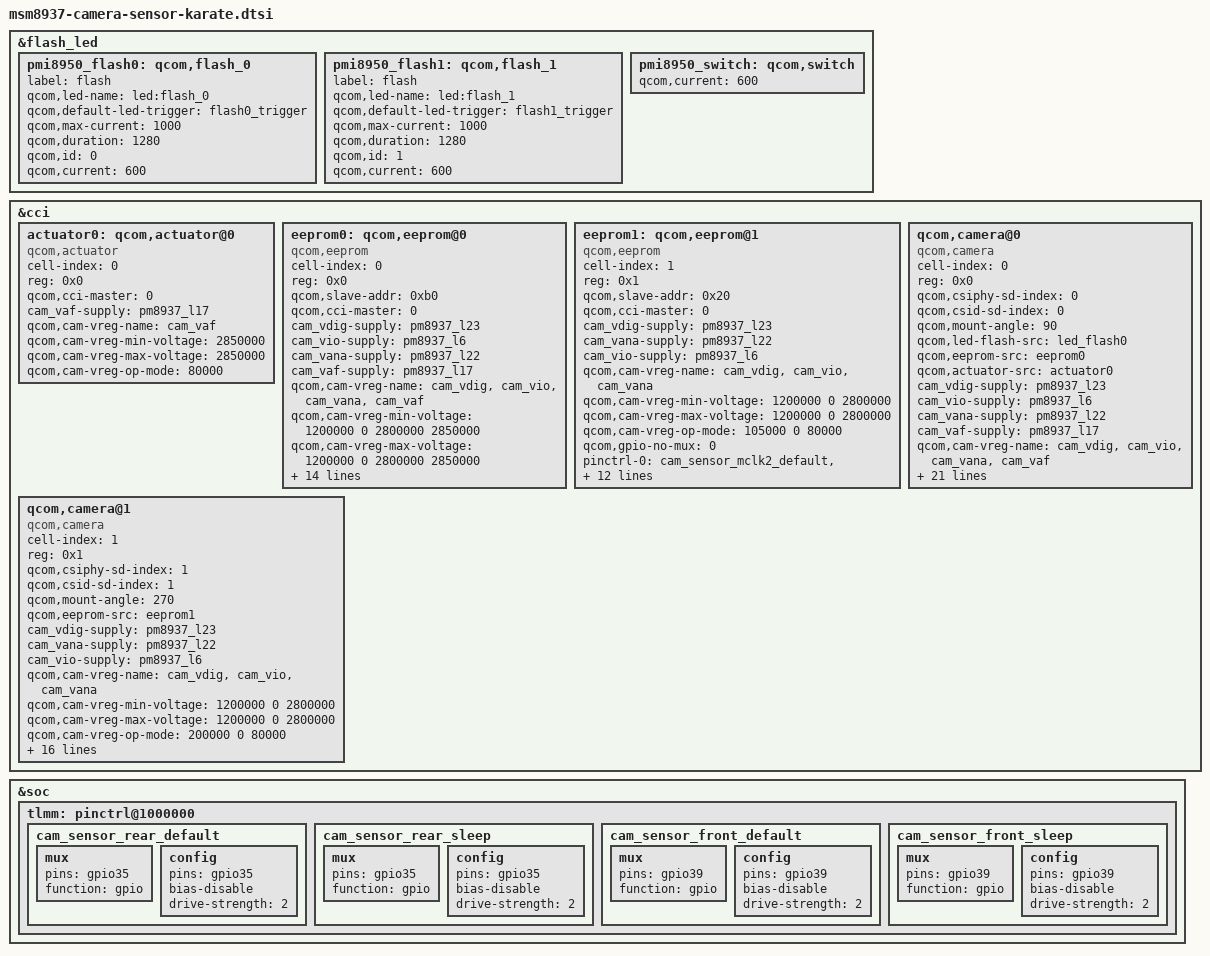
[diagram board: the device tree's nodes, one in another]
/*
 * Copyright (c) 2015-2016, The Linux Foundation. All rights reserved.
 *
 * This program is free software; you can redistribute it and/or modify
 * it under the terms of the GNU General Public License version 2 and
 * only version 2 as published by the Free Software Foundation.
 *
 * This program is distributed in the hope that it will be useful,
 * but WITHOUT ANY WARRANTY; without even the implied warranty of
 * MERCHANTABILITY or FITNESS FOR A PARTICULAR PURPOSE.  See the
 * GNU General Public License for more details.
 */

&flash_led {
        pmi8950_flash0: qcom,flash_0 {
                label = "flash";
                qcom,led-name = "led:flash_0";
                qcom,default-led-trigger =
                                "flash0_trigger";
                qcom,max-current = <1000>;
                qcom,duration = <1280>;
                qcom,id = <0>;
                qcom,current = <600>;
        };

        pmi8950_flash1: qcom,flash_1 {
                label = "flash";
                qcom,led-name = "led:flash_1";
                qcom,default-led-trigger =
                                "flash1_trigger";
                qcom,max-current = <1000>;
                qcom,duration = <1280>;
                qcom,id = <1>;
                qcom,current = <600>;
        };

        pmi8950_switch: qcom,switch {
                qcom,current = <600>;
        };
};

&cci {
	/* DW9767 */
	actuator0: qcom,actuator@0 {
		cell-index = <0>;
		reg = <0x0>;
		compatible = "qcom,actuator";
		qcom,cci-master = <0>;
		cam_vaf-supply = <&pm8937_l17>;
		qcom,cam-vreg-name = "cam_vaf";
		qcom,cam-vreg-min-voltage = <2850000>;
		qcom,cam-vreg-max-voltage = <2850000>;
		qcom,cam-vreg-op-mode = <80000>;
	};

	/* DW9767 EEPROM */
	eeprom0: qcom,eeprom@0 {
		cell-index = <0>;
		reg = <0x0>;
		compatible = "qcom,eeprom";
		qcom,slave-addr = <0xb0>;
		qcom,cci-master = <0>;
		cam_vdig-supply = <&pm8937_l23>;
		cam_vio-supply = <&pm8937_l6>;
		cam_vana-supply = <&pm8937_l22>;
		cam_vaf-supply = <&pm8937_l17>;
		qcom,cam-vreg-name = "cam_vdig", "cam_vio", "cam_vana", "cam_vaf";
		qcom,cam-vreg-min-voltage = <1200000 0 2800000 2850000>;
		qcom,cam-vreg-max-voltage = <1200000 0 2800000 2850000>;
		qcom,cam-vreg-op-mode = <200000 0 80000 100000>;
		pinctrl-names = "cam_default", "cam_suspend";
		pinctrl-0 = <&cam_sensor_mclk0_default
				&cam_sensor_rear_default>;
		pinctrl-1 = <&cam_sensor_mclk0_sleep &cam_sensor_rear_sleep>;
		gpios = <&tlmm 26 0>,
			<&tlmm 35 0>;
		qcom,gpio-standby = <1>;
		qcom,gpio-req-tbl-num = <0 1>;
		qcom,gpio-req-tbl-flags = <1 0>;
		qcom,gpio-req-tbl-label = "CAMIF_MCLK0",
			"CAM_STANDBY0";
		clocks = <&clock_gcc clk_mclk0_clk_src>,
				<&clock_gcc clk_gcc_camss_mclk0_clk>;
		clock-names = "cam_src_clk", "cam_clk";
		qcom,clock-rates = <24000000 0>;
	};

	/* IMX219 OTP */
	eeprom1: qcom,eeprom@1 {
		cell-index = <1>;
		reg = <0x1>;
		compatible = "qcom,eeprom";
		qcom,slave-addr = <0x20>;
		qcom,cci-master = <0>;

		cam_vdig-supply = <&pm8937_l23>;
		cam_vana-supply = <&pm8937_l22>;
		cam_vio-supply = <&pm8937_l6>;
		qcom,cam-vreg-name = "cam_vdig", "cam_vio", "cam_vana";
		qcom,cam-vreg-min-voltage = <1200000 0 2800000>;
		qcom,cam-vreg-max-voltage = <1200000 0 2800000>;
		qcom,cam-vreg-op-mode = <105000 0 80000>;
		qcom,gpio-no-mux = <0>;

		pinctrl-names = "cam_default", "cam_suspend";
		pinctrl-0 = <&cam_sensor_mclk2_default
				&cam_sensor_front_default>;
		pinctrl-1 = <&cam_sensor_mclk2_sleep
				&cam_sensor_front_sleep>;
		gpios = <&tlmm 28 0>,
			<&tlmm 39 0>;
		qcom,gpio-standby = <1>;
		qcom,gpio-req-tbl-num = <0 1>;
		qcom,gpio-req-tbl-flags = <1 0>;
		qcom,gpio-req-tbl-label = "CAMIF_MCLK2",
					  "CAM_STANDBY2";
		clocks = <&clock_gcc clk_mclk2_clk_src>,
				<&clock_gcc clk_gcc_camss_mclk2_clk>;
		clock-names = "cam_src_clk", "cam_clk";
		qcom,clock-rates = <24000000 0>;
	};

	/* IMX258 */
	qcom,camera@0 {
		cell-index = <0>;
		compatible = "qcom,camera";
		reg = <0x0>;
		qcom,csiphy-sd-index = <0>;
		qcom,csid-sd-index = <0>;
		qcom,mount-angle = <90>;
		qcom,led-flash-src = <&led_flash0>;
		qcom,eeprom-src = <&eeprom0>;
		qcom,actuator-src = <&actuator0>;
		cam_vdig-supply = <&pm8937_l23>;
		cam_vio-supply = <&pm8937_l6>;
		cam_vana-supply = <&pm8937_l22>;
		cam_vaf-supply = <&pm8937_l17>;
		qcom,cam-vreg-name = "cam_vdig", "cam_vio", "cam_vana", "cam_vaf";
		qcom,cam-vreg-min-voltage = <1200000 0 2800000 2850000>;
		qcom,cam-vreg-max-voltage = <1200000 0 2800000 2850000>;
		qcom,cam-vreg-op-mode = <200000 0 80000 100000>;
		pinctrl-names = "cam_default", "cam_suspend";
		pinctrl-0 = <&cam_sensor_mclk0_default &cam_sensor_rear_default>;
		pinctrl-1 = <&cam_sensor_mclk0_sleep &cam_sensor_rear_sleep>;
		gpios = <&tlmm 26 0>,
			<&tlmm 35 0>;
		qcom,gpio-standby = <1>;
		qcom,gpio-req-tbl-num = <0 1>;
		qcom,gpio-req-tbl-flags = <1 0>;
		qcom,gpio-req-tbl-label = "CAMIF_MCLK0",
			"CAM_STANDBY0";
		qcom,sensor-position = <0>;
		qcom,sensor-mode = <0>;
		qcom,cci-master = <0>;
		status = "ok";
		clocks = <&clock_gcc clk_mclk0_clk_src>,
				<&clock_gcc clk_gcc_camss_mclk0_clk>;
		clock-names = "cam_src_clk", "cam_clk";
		qcom,clock-rates = <24000000 0>;
	};

	/* IMX219 */
	qcom,camera@1 {
		cell-index = <1>;
		compatible = "qcom,camera";
		reg = <0x1>;
		qcom,csiphy-sd-index = <1>;
		qcom,csid-sd-index = <1>;
		qcom,mount-angle = <270>;
		qcom,eeprom-src = <&eeprom1>;
		cam_vdig-supply = <&pm8937_l23>;
		cam_vana-supply = <&pm8937_l22>;
		cam_vio-supply = <&pm8937_l6>;
		qcom,cam-vreg-name = "cam_vdig", "cam_vio", "cam_vana";
		qcom,cam-vreg-min-voltage = <1200000 0 2800000>;
		qcom,cam-vreg-max-voltage = <1200000 0 2800000>;
		qcom,cam-vreg-op-mode = <200000 0 80000>;
		pinctrl-names = "cam_default", "cam_suspend";
		pinctrl-0 = <&cam_sensor_mclk2_default
				&cam_sensor_front_default>;
		pinctrl-1 = <&cam_sensor_mclk2_sleep
				&cam_sensor_front_sleep>;
		gpios = <&tlmm 28 0>,
			<&tlmm 39 0>;
		qcom,gpio-standby = <1>;
		qcom,gpio-req-tbl-num = <0 1>;
		qcom,gpio-req-tbl-flags = <1 0>;
		qcom,gpio-req-tbl-label = "CAMIF_MCLK2",
			"CAM_STANDBY2";
		qcom,sensor-position = <1>;
		qcom,sensor-mode = <0>;
		qcom,cci-master = <0>;
		clocks = <&clock_gcc clk_mclk2_clk_src>,
				<&clock_gcc clk_gcc_camss_mclk2_clk>;
		clock-names = "cam_src_clk", "cam_clk";
		qcom,clock-rates = <24000000 0>;
	};
};

&soc {
	tlmm: pinctrl@1000000 {
		/delete-node/ cam_sensor_rear_default;
		/delete-node/ cam_sensor_rear_sleep;
		/delete-node/ cam_sensor_front_default;
		/delete-node/ cam_sensor_front_sleep;

		cam_sensor_rear_default: cam_sensor_rear_default {
			/* STANDBY */
			mux {
				pins = "gpio35";
				function = "gpio";
			};

			config {
				pins = "gpio35";
				bias-disable; /* No PULL */
				drive-strength = <2>; /* 2 MA */
			};
		};

		cam_sensor_rear_sleep: cam_sensor_rear_sleep {
			/* STANDBY */
			mux {
				pins = "gpio35";
				function = "gpio";
			};

			config {
				pins = "gpio35";
				bias-disable; /* No PULL */
				drive-strength = <2>; /* 2 MA */
			};
		};

		cam_sensor_front_default: cam_sensor_front_default {
			/* STANDBY */
			mux {
				pins = "gpio39";
				function = "gpio";
			};

			config {
				pins = "gpio39";
				bias-disable; /* No PULL */
				drive-strength = <2>; /* 2 MA */
			};
		};

		cam_sensor_front_sleep: cam_sensor_front_sleep {
			/* STANDBY */
			mux {
				pins = "gpio39";
				function = "gpio";
			};

			config {
				pins = "gpio39";
				bias-disable; /* No PULL */
				drive-strength = <2>; /* 2 MA */
			};
		};
	};
};
